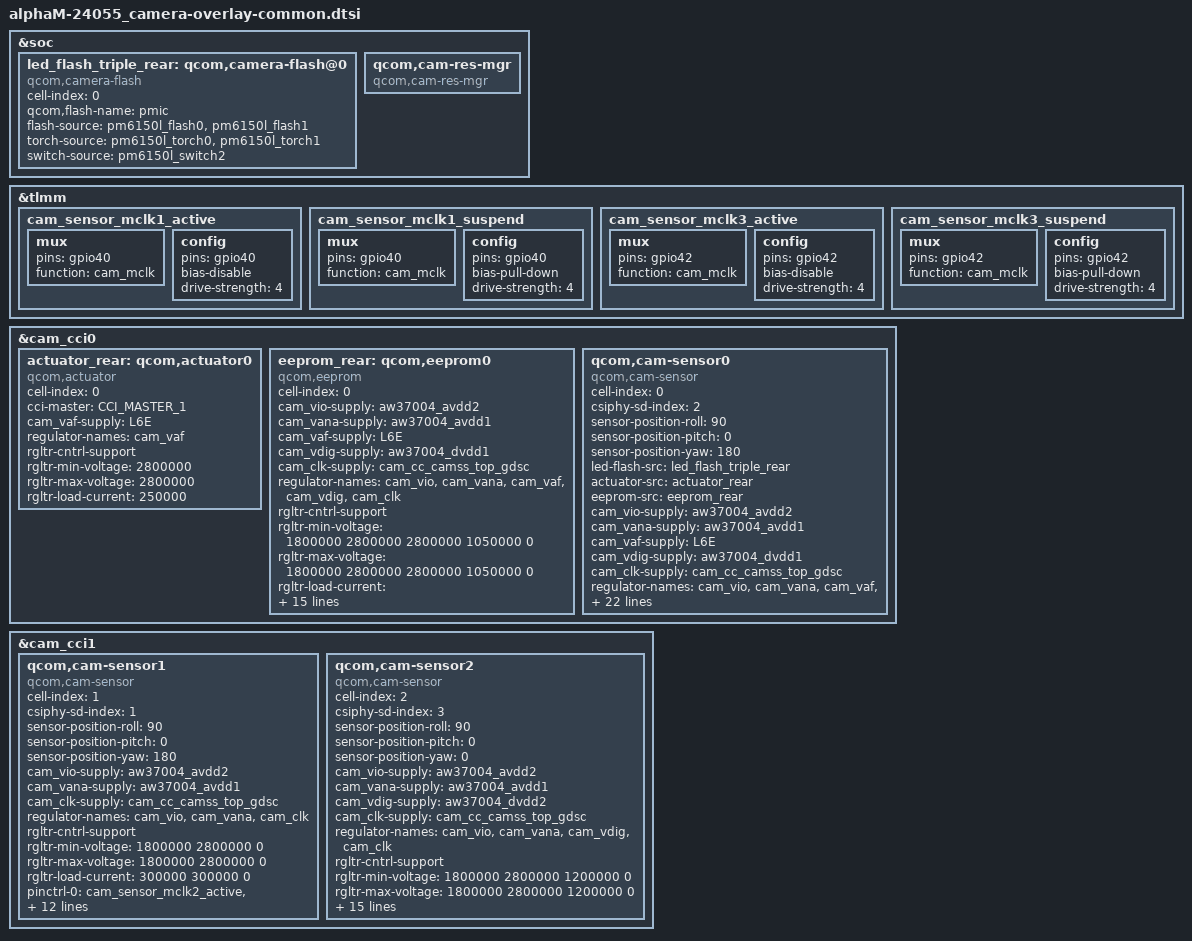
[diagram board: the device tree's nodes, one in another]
#include <dt-bindings/clock/qcom,camcc-parrot.h>
#include <dt-bindings/msm-camera.h>


&soc {

	led_flash_triple_rear: qcom,camera-flash@0 {
		cell-index = <0>;
		compatible = "qcom,camera-flash";
		qcom,flash-name = "pmic";
		flash-source = <&pm6150l_flash0 &pm6150l_flash1>;
		torch-source = <&pm6150l_torch0 &pm6150l_torch1>;
		switch-source = <&pm6150l_switch2>;
		status = "ok";
	};

	qcom,cam-res-mgr {
		compatible = "qcom,cam-res-mgr";
		status = "ok";
	};
};

&tlmm{
	cam_sensor_mclk1_active: cam_sensor_mclk1_active {
		/* MCLK1 */
		mux {
			pins = "gpio40";
			function = "cam_mclk";
		};

		config {
			pins = "gpio40";
			bias-disable; /* No PULL */
			drive-strength = <4>; /* 4 MA */
		};
	};

	cam_sensor_mclk1_suspend: cam_sensor_mclk1_suspend {
		/* MCLK1 */
		mux {
			pins = "gpio40";
			function = "cam_mclk";
		};

		config {
			pins = "gpio40";
			bias-pull-down; /* PULL DOWN */
			drive-strength = <4>; /* 4 MA */
		};
	};

	cam_sensor_mclk3_active: cam_sensor_mclk3_active {
		/* MCLK3 */
		mux {
			pins = "gpio42";
			function = "cam_mclk";
		};

		config {
			pins = "gpio42";
			bias-disable; /* No PULL */
			drive-strength = <4>; /* 4 MA */
		};
	};

	cam_sensor_mclk3_suspend: cam_sensor_mclk3_suspend {
		/* MCLK3 */
		mux {
			pins = "gpio42";
			function = "cam_mclk";
		};

		config {
			pins = "gpio42";
			bias-pull-down; /* PULL DOWN */
			drive-strength = <4>; /* 4 MA */
		};
	};
};

&cam_cci0 {

	actuator_rear: qcom,actuator0 {
		cell-index = <0>;
		compatible = "qcom,actuator";
		cci-master = <CCI_MASTER_1>;
		cam_vaf-supply = <&L6E>;
		regulator-names = "cam_vaf";
		rgltr-cntrl-support;
		rgltr-min-voltage = <2800000>;
		rgltr-max-voltage = <2800000>;
		rgltr-load-current = <250000>;
		status = "ok";

	};
	eeprom_rear: qcom,eeprom0 {
		cell-index = <0>;
		compatible = "qcom,eeprom";
		cam_vio-supply = <&aw37004_avdd2>;
		cam_vana-supply = <&aw37004_avdd1>;
		cam_vaf-supply = <&L6E>;
		cam_vdig-supply = <&aw37004_dvdd1>;
		cam_clk-supply = <&cam_cc_camss_top_gdsc>;
		regulator-names = "cam_vio", "cam_vana", "cam_vaf", "cam_vdig", "cam_clk";
		rgltr-cntrl-support;
		rgltr-min-voltage = <1800000 2800000 2800000 1050000 0>;
		rgltr-max-voltage = <1800000 2800000 2800000 1050000 0>;
		rgltr-load-current = <300000 3000000 3000000 1200000 0>;
		gpio-no-mux = <0>;
		pinctrl-names = "cam_default", "cam_suspend";
		pinctrl-0 = <&cam_sensor_mclk1_active
				 &cam_sensor_active_rst1>;
		pinctrl-1 = <&cam_sensor_mclk1_suspend
				 &cam_sensor_suspend_rst1>;
		gpios = <&tlmm 40 0>,
			<&tlmm 45 0>;
		gpio-reset = <1>;
		gpio-req-tbl-num = <0 1>;
		gpio-req-tbl-flags = <1 0>;
		gpio-req-tbl-label = "CAMIF_MCLK1",
					"CAM_RESET1";
		cci-master = <CCI_MASTER_1>;
		clocks = <&camcc CAM_CC_MCLK1_CLK>;
		clock-names = "cam_clk";
		clock-cntl-level = "nominal";
		clock-rates = <24000000>;
		status = "ok";

	};
	/* Rear*/
	qcom,cam-sensor0 {
		cell-index = <0>;
		compatible = "qcom,cam-sensor";
		csiphy-sd-index = <2>;
		sensor-position-roll = <90>;
		sensor-position-pitch = <0>;
		sensor-position-yaw = <180>;
		led-flash-src = <&led_flash_triple_rear>;
		actuator-src = <&actuator_rear>;
		eeprom-src = <&eeprom_rear>;
		cam_vio-supply = <&aw37004_avdd2>;
		cam_vana-supply = <&aw37004_avdd1>;
		cam_vaf-supply = <&L6E>;
		cam_vdig-supply = <&aw37004_dvdd1>;
		cam_clk-supply = <&cam_cc_camss_top_gdsc>;
		regulator-names = "cam_vio", "cam_vana", "cam_vaf", "cam_vdig", "cam_clk";
		rgltr-cntrl-support;
		rgltr-min-voltage = <1800000 2800000 2800000 1050000 0>;
		rgltr-max-voltage = <1800000 2800000 2800000 1050000 0>;
		rgltr-load-current = <300000 300000  300000  1200000 0>;
		gpio-no-mux = <0>;
		pinctrl-names = "cam_default", "cam_suspend";
		pinctrl-0 = <&cam_sensor_mclk1_active
				 &cam_sensor_active_rst1>;
		pinctrl-1 = <&cam_sensor_mclk1_suspend
				 &cam_sensor_suspend_rst1>;
		gpios = <&tlmm 40 0>,
			<&tlmm 45 0>;
		gpio-reset = <1>;
		gpio-req-tbl-num = <0 1>;
		gpio-req-tbl-flags = <1 0>;
		gpio-req-tbl-label = "CAMIF_MCLK1",
					"CAM_RESET1";
		cci-master = <CCI_MASTER_1>;
		clocks = <&camcc CAM_CC_MCLK1_CLK>;
		clock-names = "cam_clk";
		clock-cntl-level = "nominal";
		clock-rates = <24000000>;
		status = "ok";
	};
};

&cam_cci1 {

	/*Rear Aux*/
	qcom,cam-sensor1 {
		cell-index = <1>;
		compatible = "qcom,cam-sensor";
		csiphy-sd-index = <1>;
		sensor-position-roll = <90>;
		sensor-position-pitch = <0>;
		sensor-position-yaw = <180>;
		//eeprom-src = <&eeprom_rear_aux>;
		//led-flash-src = <&led_flash_triple_rear_aux1>;
		cam_vio-supply = <&aw37004_avdd2>;
		cam_vana-supply = <&aw37004_avdd1>;
		//cam_vdig-supply = <&aw37004_dvdd2>;
		cam_clk-supply = <&cam_cc_camss_top_gdsc>;
		//regulator-names = "cam_vio", "cam_vana", "cam_vdig", "cam_clk";
		regulator-names = "cam_vio", "cam_vana", "cam_clk";
		rgltr-cntrl-support;
		rgltr-min-voltage = <1800000 2800000  0>;
		rgltr-max-voltage = <1800000 2800000  0>;
		rgltr-load-current = <300000 300000  0>;
		pinctrl-names = "cam_default", "cam_suspend";
		pinctrl-0 = <&cam_sensor_mclk2_active
				&cam_sensor_active_rst2>;
		pinctrl-1 = <&cam_sensor_mclk2_suspend
				&cam_sensor_suspend_rst2>;
		gpios = <&tlmm 41 0>,
			<&tlmm 46 0>;
		gpio-reset = <1>;
		gpio-req-tbl-num = <0 1>;
		gpio-req-tbl-flags = <1 0>;
		gpio-req-tbl-label = "CAMIF_MCLK2",
					"CAM_RESET2";
		cci-master = <CCI_MASTER_0>;
		clocks = <&camcc CAM_CC_MCLK2_CLK>;
		clock-names = "cam_clk";
		clock-cntl-level = "nominal";
		clock-rates = <24000000>;
		status = "ok";
	};

	/*Front*/
	qcom,cam-sensor2 {
		cell-index = <2>;
		compatible = "qcom,cam-sensor";
		csiphy-sd-index = <3>;
		sensor-position-roll = <90>;
		sensor-position-pitch = <0>;
		sensor-position-yaw = <0>;
		cam_vio-supply = <&aw37004_avdd2>;
		cam_vana-supply = <&aw37004_avdd1>;
		cam_vdig-supply = <&aw37004_dvdd2>;
		cam_clk-supply = <&cam_cc_camss_top_gdsc>;
		regulator-names = "cam_vio", "cam_vana", "cam_vdig", "cam_clk";
		rgltr-cntrl-support;
		rgltr-min-voltage = <1800000 2800000 1200000 0>;
		rgltr-max-voltage = <1800000 2800000 1200000 0>;
		rgltr-load-current = <300000 300000 120000 0>;
		gpio-no-mux = <0>;
		pinctrl-names = "cam_default", "cam_suspend";
		pinctrl-0 = <&cam_sensor_mclk3_active
				 &cam_sensor_active_rst3>;
		pinctrl-1 = <&cam_sensor_mclk3_suspend
				 &cam_sensor_suspend_rst3>;
		gpios = <&tlmm 42 0>,
			<&tlmm 47 0>;
		gpio-reset = <1>;
		gpio-req-tbl-num = <0 1>;
		gpio-req-tbl-flags = <1 0>;
		gpio-req-tbl-label = "CAMIF_MCLK3",
					"CAM_RESET3";
		cci-master = <CCI_MASTER_1>;
		clocks = <&camcc CAM_CC_MCLK3_CLK>;
		clock-names = "cam_clk";
		clock-cntl-level = "nominal";
		clock-rates = <24000000>;
		status = "ok";
	};
};
